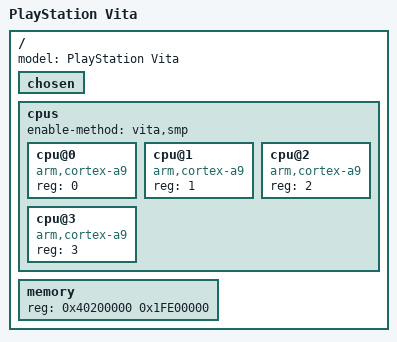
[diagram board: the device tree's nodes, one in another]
// SPDX-License-Identifier: GPL-2.0+
/*
 * Base Device Tree Source for the PlayStation Vita
 */

/dts-v1/;

/ {
	model = "PlayStation Vita";
	//compatible = "vita,vita";

	#address-cells = <1>;
	#size-cells = <1>;

	chosen {
		#address-cells = <1>;
		#size-cells = <1>;
		ranges;
	};

	cpus {
		#address-cells = <1>;
		#size-cells = <0>;
		enable-method = "vita,smp";

		cpu@0 {
			device_type = "cpu";
			compatible = "arm,cortex-a9";
			reg = <0>;
		};

		cpu@1 {
			device_type = "cpu";
			compatible = "arm,cortex-a9";
			reg = <1>;
		};

		cpu@2 {
			device_type = "cpu";
			compatible = "arm,cortex-a9";
			reg = <2>;
		};

		cpu@3 {
			device_type = "cpu";
			compatible = "arm,cortex-a9";
			reg = <3>;
		};
	};

	memory {
		device_type = "memory";
		reg = <0x40200000 0x1FE00000>;
	};
};
